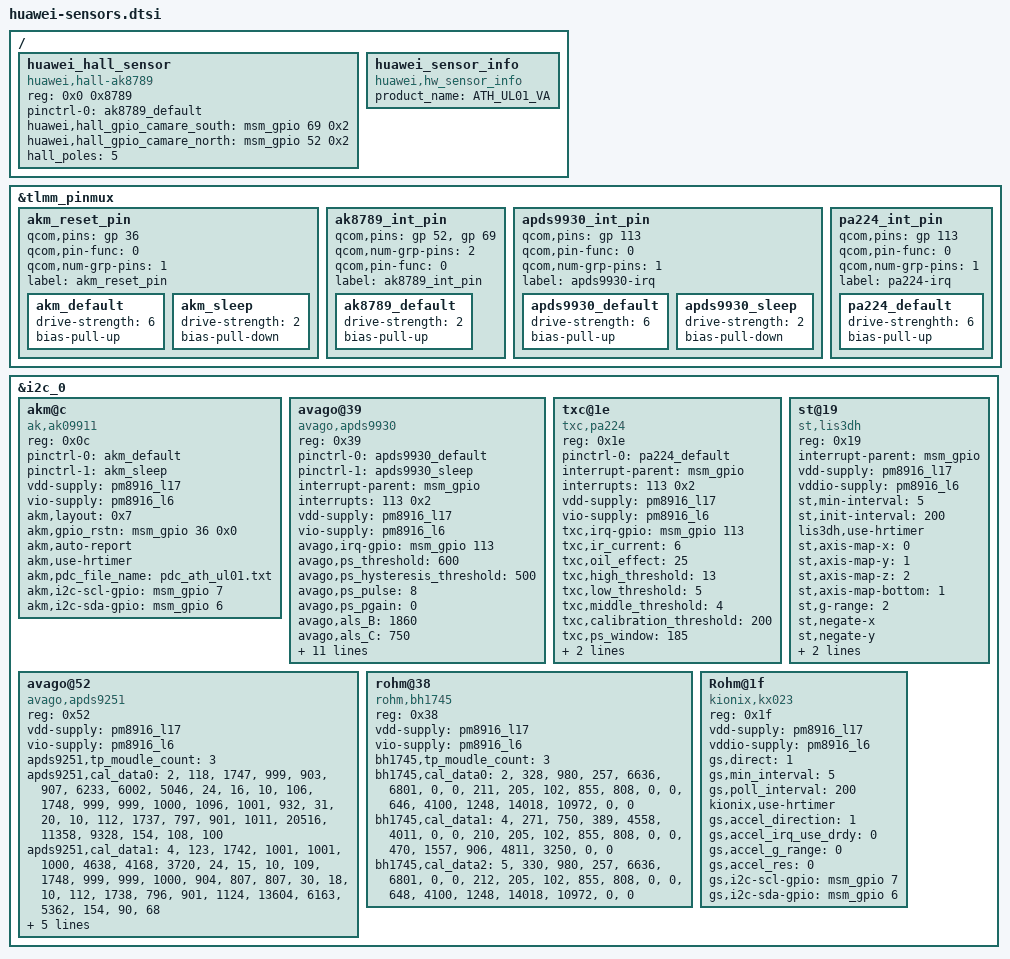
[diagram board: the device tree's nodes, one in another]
/* < DTS2015031702865 zhoujian zwx221429 20150317 begin */
/* < DTS2014121804508 wangcunyou 20141218 begin */
/*use fromdos convert file format to linux*/
/* Copyright (c) 2013 The Linux Foundation. All rights reserved.
 *
 * This program is free software; you can redistribute it and/or modify
 * it under the terms of the GNU General Public License version 2 and
 * only version 2 as published by the Free Software Foundation.
 *
 * This program is distributed in the hope that it will be useful,
 * but WITHOUT ANY WARRANTY; without even the implied warranty of
 * MERCHANTABILITY or FITNESS FOR A PARTICULAR PURPOSE.  See the
 * GNU General Public License for more details.
 */
&tlmm_pinmux {
	akm_reset_pin {
		qcom,pins = <&gp 36>;
		qcom,pin-func = <0>;
		qcom,num-grp-pins = <1>;
		label = "akm_reset_pin";
		akm_default: akm_default {
			drive-strength = <6>;
			bias-pull-up;
		};
		akm_sleep: akm_sleep {
			drive-strength = <2>;
			bias-pull-down;
		};
	};

	ak8789_int_pin {
		qcom,pins = <&gp 52>, <&gp 69>;
		qcom,num-grp-pins = <2>;
		qcom,pin-func = <0>;
		label = "ak8789_int_pin";
		ak8789_default: ak8789_default {
			  drive-strength = <2>;
			  bias-pull-up;
		};
	};
	apds9930_int_pin {
		qcom,pins = <&gp 113>;
		qcom,pin-func = <0>;
		qcom,num-grp-pins = <1>;
		label = "apds9930-irq";
		apds9930_default: apds9930_default {
			drive-strength = <6>;
			bias-pull-up;
		};
		apds9930_sleep: apds9930_sleep {
			drive-strength = <2>;
			bias-pull-down;
		};
	};
	pa224_int_pin {
		qcom,pins = <&gp 113>;
		qcom,pin-func = <0>;
		qcom,num-grp-pins = <1>;
		label = "pa224-irq";
		pa224_default: pa224_default {
			drive-strenghth = <6>;
			bias-pull-up;
		};
	};
};

&i2c_0 { /* BLSP1 QUP2 */
	akm@c {
		compatible = "ak,ak09911";
		reg = <0x0c>;
		pinctrl-names = "default","sleep";
		pinctrl-0 = <&akm_default>;
		pinctrl-1 = <&akm_sleep>;
		vdd-supply = <&pm8916_l17>;
		vio-supply = <&pm8916_l6>;
		akm,layout = <0x7>;
		akm,gpio_rstn = <&msm_gpio 36 0x0>;
		akm,auto-report;
		/* < DTS2015052009130 hufeng 20150601 begin */
		akm,use-hrtimer;
		/*  DTS2015052009130 hufeng 20150601 end > */
		/* < DTS2015032800844 caowei 20150319 begin */
		akm,pdc_file_name = "pdc_ath_ul01.txt";
		akm,i2c-scl-gpio = <&msm_gpio 7 0x0>;
		akm,i2c-sda-gpio = <&msm_gpio 6 0x0>;
		/* DTS2015032800844 caowei 20150319 end > */
	};

	avago@39 {
		compatible = "avago,apds9930";
		reg = <0x39>;
		pinctrl-names = "default","sleep";
		pinctrl-0 = <&apds9930_default>;
		pinctrl-1 = <&apds9930_sleep>;
		interrupt-parent = <&msm_gpio>;
		interrupts = <113 0x2>;
		vdd-supply = <&pm8916_l17>;
		vio-supply = <&pm8916_l6>;
		avago,irq-gpio = <&msm_gpio 113 0x2>;
		avago,ps_threshold = <600>;
		avago,ps_hysteresis_threshold = <500>;
		avago,ps_pulse = <8>;
		avago,ps_pgain = <0>;
		avago,als_B = <1860>;
		avago,als_C = <750>;
		avago,als_D = <1290>;
		avago,ga_value = <48>;
	        avago,ga_a_value = <112>;
		avago,ga_c_value = <450>;
		avago,ga_d_value = <162>;
		avago,window = <110>;
		avago,wave = <84>;
		avago,ga_e_value = <220>;
		avago,ga_f_value = <43>;
		/* < DTS2015032800844 caowei 20150319 begin */
		avago,i2c-scl-gpio = <&msm_gpio 7 0x0>;
		avago,i2c-sda-gpio = <&msm_gpio 6 0x0>;
		/* DTS2015032800844 caowei 20150319 end > */
	};
	txc@1e {
		compatible = "txc,pa224";
		reg = <0x1e>;
		pinctrl-names = "default";
		pinctrl-0 = <&pa224_default>;
		interrupt-parent = <&msm_gpio>;
		interrupts = <113 0x2>;
		vdd-supply = <&pm8916_l17>;
		vio-supply = <&pm8916_l6>;
		txc,irq-gpio = <&msm_gpio 113 0x2>;
		/* < DTS2015051901259 wushengyu 20150528 begin */
		/* < DTS2015060307420 chenyang 20150603 begin */
		/* < DTS2015061607055 chenyang 20150603 begin */
		/*IR CURRENT 10MA*/
		txc,ir_current = <6>;
		/* < DTS2015062400454 wushengyu 20150624 begin */
		/* < DTS2015062703786 wushengyu 20150627 begin */
		txc,oil_effect = <25>;
		/* DTS2015062703786 wushengyu 20150627 end > */
		/* DTS2015062400454 wushengyu 20150624 end > */
		txc,high_threshold = <13>;
		txc,low_threshold = <5>;
		txc,middle_threshold = <4>;
		txc,calibration_threshold = <200>;
		/* DTS2015061607055 chenyang 20150603 end > */
		/* DTS2015060307420 chenyang 20150603 end > */
		/* DTS2015051901259 wushengyu 20150528 end > */
		/* < DTS2015030203957  wushengyu 20150302 begin */
		/* < DTS2015030605077   wushengyu 20150306 begin */
		/* < DTS2015032301235   chenyang 20150423 begin */
		txc,ps_window = <185>;
		txc,ps_wave = <20>;
		/* DTS2015032301235 chenyang 20150423 end > */
		/* DTS2015030605077   wushengyu 20150306 end > */
		txc,ps_defalt_crosstalk = <50>;
		/* DTS2015030203957  wushengyu 20150302 end > */
	};
	/* < DTS2015082604454 wuying/wx221431 20150826 begin */
	avago@52 {
		compatible = "avago,apds9251";
		reg = <0x52>;
		vdd-supply = <&pm8916_l17>;
		vio-supply = <&pm8916_l6>;
		apds9251,tp_moudle_count = <3>;
		/*[module_id] [CCT_M] [CCT_N] [H] [A] [D] [LUX_P] [LUX_Q] [LUX_R] [cofficient0] [cofficient1] [cofficient2]*/
		apds9251,cal_data0 = "2","118","1747","999","903","907","6233","6002","5046","24","16","10",
		/*[CCT_M] [CCT_N] [H] [A] [D] [LUX_P] [LUX_Q] [LUX_R] [cofficient0] [cofficient1] [cofficient2]*/
		"106","1748","999","999","1000","1096","1001","932","31","20","10",
		/*[CCT_M] [CCT_N] [H] [A] [D] [LUX_P] [LUX_Q] [LUX_R] [cofficient0] [cofficient1] [cofficient2]*/
		"112","1737","797","901","1011","20516","11358","9328","154","108","100";
		/*[module_id] [CCT_M] [CCT_N] [H] [A] [D] [LUX_P] [LUX_Q] [LUX_R] [cofficient0] [cofficient1] [cofficient2]*/
		apds9251,cal_data1 = "4","123","1742","1001","1001","1000","4638","4168","3720","24","15","10",
		/*[CCT_M] [CCT_N] [H] [A] [D] [LUX_P] [LUX_Q] [LUX_R] [cofficient0] [cofficient1] [cofficient2]*/
		"109","1748","999","999","1000","904","807","807","30","18","10",
		/*[CCT_M] [CCT_N] [H] [A] [D] [LUX_P] [LUX_Q] [LUX_R] [cofficient0] [cofficient1] [cofficient2]*/
		"112","1738","796","901","1124","13604","6163","5362","154","90","68";
		/*[module_id] [CCT_M] [CCT_N] [H] [A] [D] [LUX_P] [LUX_Q] [LUX_R] [cofficient0] [cofficient1] [cofficient2]*/
		apds9251,cal_data2 = "5","9976","1490","948","1048","1150","2470","2475","2261","25","15","10",
		/*[CCT_M] [CCT_N] [H] [A] [D] [LUX_P] [LUX_Q] [LUX_R] [cofficient0] [cofficient1] [cofficient2]*/
		"6491","1636","946","1054","1159","1043","1004","940","30","19","10",
		/*[CCT_M] [CCT_N] [H] [A] [D] [LUX_P] [LUX_Q] [LUX_R] [cofficient0] [cofficient1] [cofficient2]*/
		"14588","1008","939","1211","1256","13043","11270","9600","58","25","10";
	};
	/* DTS2015082604454 wuying/wx221431 20150826 end > */
	rohm@38 {
		compatible = "rohm,bh1745";
		reg = <0x38>;
		vdd-supply = <&pm8916_l17>;
		vio-supply = <&pm8916_l6>;
		/* < DTS2015040700192 wushengyu 20150407 begin */
		/* < DTS2015032301235 chenyang 20150423 begin */
		/* < DTS2015073101039 chenyang 20150731 begin */
		/* < DTS2015082004661 chenyang/cwx206652 20150820 begin */
		bh1745,tp_moudle_count = <3>;
		/*JDI [module_id] [golden judge] r[0] r[1] g[0] g[1] b[0] b[1]*/
		bh1745,cal_data0 = "2","328","980","257","6636","6801","0","0",
		/*[white judge] r[0] r[1] g[0]  g[1] b[0] b[1]*/
		"211","205","102","855","808","0","0",
		/*[blue judge] r[0] r[1] g[0] g[1] b[0] b[1]*/
		"646","4100","1248","14018","10972","0","0";
		/*BOE [module_id] [golden judge] r[0] r[1] g[0] g[1] b[0] b[1]*/
		bh1745,cal_data1 = "4","271","750","389","4558","4011","0","0",
		/*[white judge] r[0] r[1] g[0]  g[1] b[0] b[1]*/
		"210","205","102","855","808","0","0",
		/*[blue judge] r[0] r[1] g[0] g[1] b[0] b[1]*/
		"470","1557","906","4811","3250","0","0";
		/*LG [module_id] [golden judge] r[0] r[1] g[0] g[1] b[0] b[1]*/
		bh1745,cal_data2 = "5","330","980","257","6636","6801","0","0",
		/*[white judge] r[0] r[1] g[0]  g[1] b[0] b[1]*/
		"212","205","102","855","808","0","0",
		/*[blue judge] r[0] r[1] g[0] g[1] b[0] b[1]*/
		"648","4100","1248","14018","10972","0","0";
		/* DTS2015082004661 chenyang/cwx206652 20150820 end > */
		/* DTS2015073101039 chenyang 20150731 end > */
		/* DTS2015032301235 chenyang 20150423 end > */
		/* DTS2015040700192 wushengyu 20150407 end > */
	};

	st@19 {
		compatible = "st,lis3dh";
		reg = <0x19>;
		interrupt-parent = <&msm_gpio>;
		vdd-supply = <&pm8916_l17>;
		vddio-supply = <&pm8916_l6>;
		st,min-interval = <5>;
		st,init-interval = <200>;
		/*  DTS2015052009130 hufeng 20150601 end > */
		lis3dh,use-hrtimer;
		/* < DTS2015052009130 hufeng 20150601 begin */
		st,axis-map-x = <0>;
		st,axis-map-y = <1>;
		st,axis-map-z = <2>;
		/*1 is bottom and others means top*/
		st,axis-map-bottom=<1>;
		st,g-range = <2>;
		st,negate-x;
		st,negate-y;
		/* < DTS2015032800844 caowei 20150319 begin */
		st,i2c-scl-gpio = <&msm_gpio 7 0x0>;
		st,i2c-sda-gpio = <&msm_gpio 6 0x0>;
		/* DTS2015032800844 caowei 20150319 end > */
	};
	Rohm@1f {
		compatible = "kionix,kx023";
		reg = <0x1f>;
		vdd-supply = <&pm8916_l17>;
		vddio-supply = <&pm8916_l6>;
		/* < DTS2014102905500 chuguoliang 20141029 begin */
		/*1 is bottom and others means top*/
		gs,direct = <1>;
		/* DTS2014102905500 chuguoliang 20141029 end > */
		gs,min_interval = <5>;
		gs,poll_interval = <200>;
		/* < DTS2015052009130 hufeng 20150601 begin */
		kionix,use-hrtimer;
		/*  DTS2015052009130 hufeng 20150601 end > */
		gs,accel_direction = <1>;
		gs,accel_irq_use_drdy = <0>;
		gs,accel_g_range = <0>;
		gs,accel_res = <0>;
		/* < DTS2015032800844 caowei 20150319 begin */
		gs,i2c-scl-gpio = <&msm_gpio 7 0x0>;
		gs,i2c-sda-gpio = <&msm_gpio 6 0x0>;
		/* DTS2015032800844 caowei 20150319 end > */
	};
};
/{
	huawei_hall_sensor{
		compatible = "huawei,hall-ak8789";
		reg = <0x0 0x8789>;
		pinctrl-names = "default";
		pinctrl-0 = <&ak8789_default>;
		/* < DTS2014122304450 wangcunyou 20141223 begin */
		huawei,hall_gpio_camare_south = <&msm_gpio 69 0x2>;
		huawei,hall_gpio_camare_north = <&msm_gpio 52 0x2>;
		hall_poles = <5>;
		/* DTS2014122304450 wangcunyou 20141222 end > */
		status = "ok";
	};
};
/* DTS2014121804508 wangcunyou 20141218 end > */
/* < DTS2015020511013 wangcunyou 20150205 begin */
/{
	huawei_sensor_info {
		compatible = "huawei,hw_sensor_info";
		product_name = "ATH_UL01_VA";
	};
};
/* DTS2015020511013 wangcunyou 20150205 end > */
/* DTS2015031702865 zhoujian zwx221429 20150317 end > */
